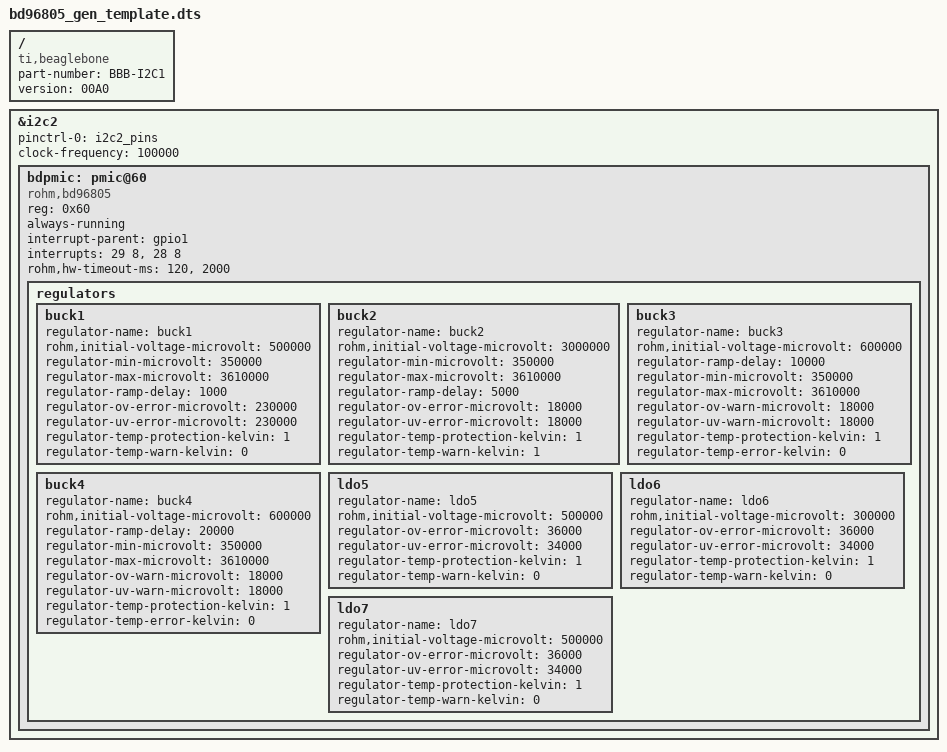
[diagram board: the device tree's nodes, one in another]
/dts-v1/;
/plugin/;

/{ /* this is our device tree overlay root node */

	compatible = "ti,beaglebone", "ti,beaglebone-black";
	part-number = "BBB-I2C1"; // you can choose any name here but it should be memorable
 	version = "00A0";

	fragment@1 {
		target = <&i2c2>;

		__overlay__ {
			pinctrl-0 = <&i2c2_pins>;
			clock-frequency = <100000>;
			status = "okay";

			bdpmic: pmic@60 { /* the "test" defined as child of the i2c2 bus */
				reg = <0x60>;
/*				pinctrl-names = "default"; */
				compatible = "rohm,bd96805";
				always-running;
				/* GPIO 1_29 - (connector 8, pin 26) for intb_irq */
				/* GPIO 1_28 - (connector 9, pin 12) for errb_irq */
				interrupt-parent = <&gpio1>;
/*				interrupts = <29 LEVEL_LOW, 0 LEVEL_LOW>; */
				interrupts = <29 8>,<28 8>;
/*				interrupts = <28 8>; */
				interrupt-names = "intb", "errb";
				rohm,hw-timeout-ms = <120>, <2000>;
/*				interrupt-names = "intb"; */
				/* 1500 ms cold reset */

				regulators {
					buck1 {
						regulator-name = "buck1";
						rohm,initial-voltage-microvolt = <500000>;
						regulator-min-microvolt = <350000>;
						/*
						   This (1650000 uV) is Ok if initial-voltage is set.
						   The upstreamed "simple" driver does not support STBY-
						   only configs though, so INI_VOUT is the default 1.8V.

						   In order to allow testing the TUNE range, max should be
						   3.3V + max tune 310 mV => 3610000 uV
						 */
/*						regulator-max-microvolt = <1650000>; */
						regulator-max-microvolt = <3610000>;
/*						regulator-boot-on; */
/*						regulator-always-on; */
						regulator-ramp-delay = <1000>;
/*						regulator-ov-protection-microvolt = <1>; */
						regulator-ov-error-microvolt = <230000>;
/*						regulator-uv-protection-microvolt = <1>; */
						regulator-uv-error-microvolt = <230000>;
						regulator-temp-protection-kelvin = <1>;
						regulator-temp-warn-kelvin = <0>;
					};
					buck2 {
						regulator-name = "buck2";
						rohm,initial-voltage-microvolt = <3000000>;
						/*
						  Default voltage seems to be 1100000
						  i2cget reads 0x78 from address 0x22
						*/
						regulator-min-microvolt = <350000>;
						regulator-max-microvolt = <3610000>;
						regulator-ramp-delay = <5000>;
/*						regulator-ov-protection-microvolt = <1>; */
						regulator-ov-error-microvolt = <18000>;
						regulator-uv-error-microvolt = <18000>;
						regulator-temp-protection-kelvin = <1>;
						regulator-temp-warn-kelvin = <1>;
					};
					buck3 {
						regulator-name = "buck3";
						rohm,initial-voltage-microvolt = <600000>;
						regulator-ramp-delay = <10000>;
						regulator-min-microvolt = <350000>;
						regulator-max-microvolt = <3610000>;
						regulator-ov-warn-microvolt = <18000>;
						regulator-uv-warn-microvolt = <18000>;
						regulator-temp-protection-kelvin = <1>;
						regulator-temp-error-kelvin = <0>;
					};
					buck4 {
						regulator-name = "buck4";
						rohm,initial-voltage-microvolt = <600000>;
						regulator-ramp-delay = <20000>;
						regulator-min-microvolt = <350000>;
						regulator-max-microvolt = <3610000>;
						regulator-ov-warn-microvolt = <18000>;
						regulator-uv-warn-microvolt = <18000>;
						regulator-temp-protection-kelvin = <1>;
						regulator-temp-error-kelvin = <0>;
					};
					ldo5 {
						regulator-name = "ldo5";
						rohm,initial-voltage-microvolt = <500000>;
/*						regulator-always-on; */
						regulator-ov-error-microvolt = <36000>;
						regulator-uv-error-microvolt = <34000>;
						regulator-temp-protection-kelvin = <1>;
						regulator-temp-warn-kelvin = <0>;
					};

					ldo6 {
						regulator-name = "ldo6";
						rohm,initial-voltage-microvolt = <300000>;
/*						regulator-always-on; */
						regulator-ov-error-microvolt = <36000>;
						regulator-uv-error-microvolt = <34000>;
						regulator-temp-protection-kelvin = <1>;
						regulator-temp-warn-kelvin = <0>;
					};

					ldo7 {
						regulator-name = "ldo7";
						rohm,initial-voltage-microvolt = <500000>;
						regulator-ov-error-microvolt = <36000>;
						regulator-uv-error-microvolt = <34000>;
						regulator-temp-protection-kelvin = <1>;
						regulator-temp-warn-kelvin = <0>;
					};
				};
			};
		};
	};
}; /* root node end */
